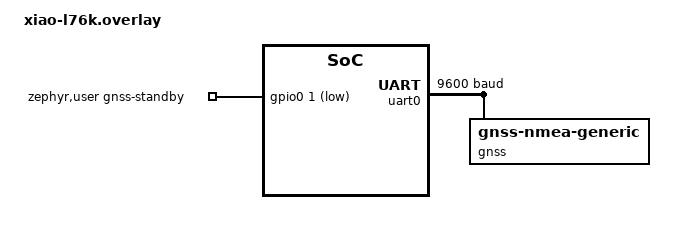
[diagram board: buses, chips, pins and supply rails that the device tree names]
/* SPDX-License-Identifier: GPL-3.0-only */
/* Seeed L76K only, with the conflicting expansion RESET disconnected from
 * the Wio-SX1262 SPI pins. The firmware never configures that reset line. */
#include <zephyr/dt-bindings/gpio/gpio.h>
/ {
	zephyr,user {
		gnss-standby-gpios = <&gpio0 1 GPIO_ACTIVE_LOW>;
	};
};

/* Board pinctrl maps RX to GPIO44 and TX to GPIO43. The passive NMEA driver
 * transmits no receiver configuration, polling, or reset commands. */
&uart0 {
	status = "okay";
	current-speed = <9600>;
	gnss: gnss {
		compatible = "gnss-nmea-generic";
	};
};
